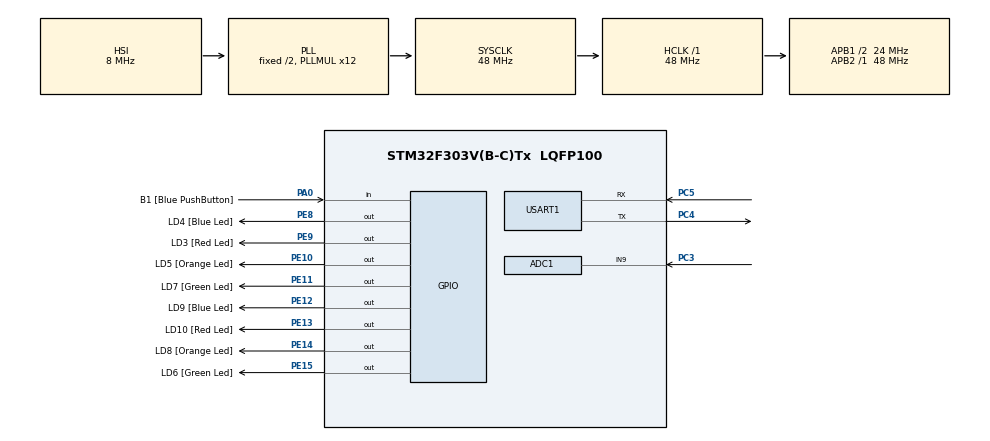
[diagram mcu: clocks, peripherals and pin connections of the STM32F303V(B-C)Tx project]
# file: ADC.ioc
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ADC1.Channel-0\#ChannelRegularConversion=ADC_CHANNEL_9
ADC1.Channel-1\#ChannelRegularConversion=ADC_CHANNEL_9
ADC1.Channel-2\#ChannelRegularConversion=ADC_CHANNEL_9
ADC1.ClockPrescaler=ADC_CLOCK_SYNC_PCLK_DIV2
ADC1.NbrOfConversion=3
ADC1.NbrOfConversionFlag=1
ADC1.Offset-0\#ChannelRegularConversion=0
ADC1.Offset-1\#ChannelRegularConversion=0
ADC1.Offset-2\#ChannelRegularConversion=0
ADC1.OffsetNumber-0\#ChannelRegularConversion=ADC_OFFSET_NONE
ADC1.OffsetNumber-1\#ChannelRegularConversion=ADC_OFFSET_NONE
ADC1.OffsetNumber-2\#ChannelRegularConversion=ADC_OFFSET_NONE
ADC1.Rank-0\#ChannelRegularConversion=1
ADC1.Rank-1\#ChannelRegularConversion=2
ADC1.Rank-2\#ChannelRegularConversion=3
ADC1.Resolution=ADC_RESOLUTION_8B
ADC1.SamplingTime-0\#ChannelRegularConversion=ADC_SAMPLETIME_1CYCLE_5
ADC1.SamplingTime-1\#ChannelRegularConversion=ADC_SAMPLETIME_1CYCLE_5
ADC1.SamplingTime-2\#ChannelRegularConversion=ADC_SAMPLETIME_1CYCLE_5
ADC1.SamplingTimeOPAMP-0\#ChannelRegularConversion=ADC_SAMPLETIME_19CYCLES_5
ADC1.SamplingTimeOPAMP-1\#ChannelRegularConversion=ADC_SAMPLETIME_19CYCLES_5
ADC1.SamplingTimeOPAMP-2\#ChannelRegularConversion=ADC_SAMPLETIME_19CYCLES_5
ADC1.master=1
Mcu.Family=STM32F3
Mcu.Name=STM32F303V(B-C)Tx
Mcu.Package=LQFP100
NVIC.PriorityGroup=NVIC_PRIORITYGROUP_0
PA0.GPIO_Label=B1 [Blue PushButton]
PA0.GPIO_Mode=GPIO_MODE_INPUT
PA0.GPIO_PuPd=GPIO_NOPULL
PA0.Signal=GPIO_Input
PA11.GPIO_Label=DM
PA11.Signal=USB_DM
PA12.GPIO_Label=DP
PA12.Signal=USB_DP
PA13.GPIO_Label=SWDIO
PA13.Signal=SYS_JTMS-SWDIO
PA14.GPIO_Label=SWCLK
PA14.Signal=SYS_JTCK-SWCLK
PB3.GPIO_Label=SWO
PB3.Signal=SYS_JTDO-TRACESWO
PC14-OSC32_IN.GPIO_Label=OSC32_IN
PC14-OSC32_IN.Signal=RCC_OSC32_IN
PC15-OSC32_OUT.GPIO_Label=OSC32_OUT
PC15-OSC32_OUT.Signal=RCC_OSC32_OUT
PC3.Signal=ADCx_IN9
PC4.Mode=Asynchronous
PC4.Signal=USART1_TX
PC5.Mode=Asynchronous
PC5.Signal=USART1_RX
PE10.GPIO_Label=LD5 [Orange Led]
PE10.GPIO_ModeDefaultOutputPP=GPIO_MODE_OUTPUT_PP
PE10.GPIO_PuPd=GPIO_NOPULL
PE10.GPIO_Speed=GPIO_SPEED_FREQ_LOW
PE10.Signal=GPIO_Output
PE11.GPIO_Label=LD7 [Green Led]
PE11.GPIO_ModeDefaultOutputPP=GPIO_MODE_OUTPUT_PP
PE11.GPIO_PuPd=GPIO_NOPULL
PE11.GPIO_Speed=GPIO_SPEED_FREQ_LOW
PE11.Signal=GPIO_Output
PE12.GPIO_Label=LD9 [Blue Led]
PE12.GPIO_ModeDefaultOutputPP=GPIO_MODE_OUTPUT_PP
PE12.GPIO_PuPd=GPIO_NOPULL
PE12.GPIO_Speed=GPIO_SPEED_FREQ_LOW
PE12.Signal=GPIO_Output
PE13.GPIO_Label=LD10 [Red Led]
PE13.GPIO_ModeDefaultOutputPP=GPIO_MODE_OUTPUT_PP
PE13.GPIO_PuPd=GPIO_NOPULL
PE13.GPIO_Speed=GPIO_SPEED_FREQ_LOW
PE13.Signal=GPIO_Output
PE14.GPIO_Label=LD8 [Orange Led]
PE14.GPIO_ModeDefaultOutputPP=GPIO_MODE_OUTPUT_PP
PE14.GPIO_PuPd=GPIO_NOPULL
PE14.GPIO_Speed=GPIO_SPEED_FREQ_LOW
PE14.Signal=GPIO_Output
PE15.GPIO_Label=LD6 [Green Led]
PE15.GPIO_ModeDefaultOutputPP=GPIO_MODE_OUTPUT_PP
PE15.GPIO_PuPd=GPIO_NOPULL
PE15.GPIO_Speed=GPIO_SPEED_FREQ_LOW
PE15.Signal=GPIO_Output
PE8.GPIO_Label=LD4 [Blue Led]
PE8.GPIO_ModeDefaultOutputPP=GPIO_MODE_OUTPUT_PP
PE8.GPIO_PuPd=GPIO_NOPULL
PE8.GPIO_Speed=GPIO_SPEED_FREQ_LOW
PE8.Signal=GPIO_Output
PE9.GPIO_Label=LD3 [Red Led]
PE9.GPIO_ModeDefaultOutputPP=GPIO_MODE_OUTPUT_PP
PE9.GPIO_PuPd=GPIO_NOPULL
PE9.GPIO_Speed=GPIO_SPEED_FREQ_LOW
PE9.Signal=GPIO_Output
PF0-OSC_IN.GPIO_Label=OSC_IN
PF0-OSC_IN.Signal=RCC_OSC_IN
PF1-OSC_OUT.GPIO_Label=OSC_OUT
PF1-OSC_OUT.Signal=RCC_OSC_OUT
ProjectManager.HeapSize=0x200
ProjectManager.StackSize=0x400
ProjectManager.TargetToolchain=STM32CubeIDE
RCC.AHBFreq_Value=48000000
RCC.APB1CLKDivider=RCC_HCLK_DIV2
RCC.APB1Freq_Value=24000000
RCC.APB1TimFreq_Value=48000000
RCC.APB2Freq_Value=48000000
RCC.APB2TimFreq_Value=48000000
RCC.CortexFreq_Value=48000000
RCC.HCLKFreq_Value=48000000
RCC.HSE_VALUE=8000000
RCC.HSI_VALUE=8000000
RCC.LSE_VALUE=32768
RCC.PLLMUL=RCC_PLL_MUL12
RCC.SYSCLKFreq_VALUE=48000000
RCC.SYSCLKSourceVirtual=RCC_SYSCLKSOURCE_PLLCLK
RCC.USBFreq_Value=48000000
SH.ADCx_IN9.0=ADC1_IN9,IN9-Single-Ended
USART1.VirtualMode-Asynchronous=VM_ASYNC
board=STM32F3DISCOVERY

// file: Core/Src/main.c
/* USER CODE BEGIN Header */
/**
  ******************************************************************************
  * @file           : main.c
  * @brief          : Main program body
  ******************************************************************************
  * @attention
  *
  * Copyright (c) 2025 STMicroelectronics.
  * All rights reserved.
  *
  * This software is licensed under terms that can be found in the LICENSE file
  * in the root directory of this software component.
  * If no LICENSE file comes with this software, it is provided AS-IS.
  *
  ******************************************************************************
  */
/* USER CODE END Header */
#include "main.h"

/* USER CODE BEGIN Includes */
#include <program.h>

/* USER CODE END Includes */

ADC_HandleTypeDef hadc1;

UART_HandleTypeDef huart1;

void SystemClock_Config(void);
static void MX_GPIO_Init(void);
static void MX_ADC1_Init(void);
static void MX_USART1_UART_Init(void);

int main(void)
{

  /* MCU Configuration--------------------------------------------------------*/

  /* Reset of all peripherals, Initializes the Flash interface and the Systick. */
  HAL_Init();

  /* Configure the system clock */
  SystemClock_Config();

  /* Initialize all configured peripherals */
  MX_GPIO_Init();
  MX_ADC1_Init();
  MX_USART1_UART_Init();
  /* USER CODE BEGIN 2 */
  extern __attribute__((noreturn)) void program(void);
  program();

  __builtin_unreachable();
  /* USER CODE END 2 */

  /* Infinite loop */
  while (1)
  {

  }
}

void SystemClock_Config(void)
{
  RCC_OscInitTypeDef RCC_OscInitStruct = {0};
  RCC_ClkInitTypeDef RCC_ClkInitStruct = {0};
  RCC_PeriphCLKInitTypeDef PeriphClkInit = {0};

  /** Initializes the RCC Oscillators according to the specified parameters
  * in the RCC_OscInitTypeDef structure.
  */
  RCC_OscInitStruct.OscillatorType = RCC_OSCILLATORTYPE_HSI;
  RCC_OscInitStruct.HSIState = RCC_HSI_ON;
  RCC_OscInitStruct.HSICalibrationValue = RCC_HSICALIBRATION_DEFAULT;
  RCC_OscInitStruct.PLL.PLLState = RCC_PLL_ON;
  RCC_OscInitStruct.PLL.PLLSource = RCC_PLLSOURCE_HSI;
  RCC_OscInitStruct.PLL.PLLMUL = RCC_PLL_MUL12;
  if (HAL_RCC_OscConfig(&RCC_OscInitStruct) != HAL_OK)
  {
    Error_Handler();
  }

  /** Initializes the CPU, AHB and APB buses clocks
  */
  RCC_ClkInitStruct.ClockType = RCC_CLOCKTYPE_HCLK|RCC_CLOCKTYPE_SYSCLK
                              |RCC_CLOCKTYPE_PCLK1|RCC_CLOCKTYPE_PCLK2;
  RCC_ClkInitStruct.SYSCLKSource = RCC_SYSCLKSOURCE_PLLCLK;
  RCC_ClkInitStruct.AHBCLKDivider = RCC_SYSCLK_DIV1;
  RCC_ClkInitStruct.APB1CLKDivider = RCC_HCLK_DIV2;
  RCC_ClkInitStruct.APB2CLKDivider = RCC_HCLK_DIV1;

  if (HAL_RCC_ClockConfig(&RCC_ClkInitStruct, FLASH_LATENCY_1) != HAL_OK)
  {
    Error_Handler();
  }
  PeriphClkInit.PeriphClockSelection = RCC_PERIPHCLK_USART1;
  PeriphClkInit.Usart1ClockSelection = RCC_USART1CLKSOURCE_PCLK2;
  if (HAL_RCCEx_PeriphCLKConfig(&PeriphClkInit) != HAL_OK)
  {
    Error_Handler();
  }
}

static void MX_ADC1_Init(void)
{

  ADC_MultiModeTypeDef multimode = {0};
  ADC_ChannelConfTypeDef sConfig = {0};

  /** Common config
  */
  hadc1.Instance = ADC1;
  hadc1.Init.ClockPrescaler = ADC_CLOCK_SYNC_PCLK_DIV2;
  hadc1.Init.Resolution = ADC_RESOLUTION_8B;
  hadc1.Init.ScanConvMode = ADC_SCAN_ENABLE;
  hadc1.Init.ContinuousConvMode = DISABLE;
  hadc1.Init.DiscontinuousConvMode = DISABLE;
  hadc1.Init.ExternalTrigConvEdge = ADC_EXTERNALTRIGCONVEDGE_NONE;
  hadc1.Init.ExternalTrigConv = ADC_SOFTWARE_START;
  hadc1.Init.DataAlign = ADC_DATAALIGN_RIGHT;
  hadc1.Init.NbrOfConversion = 3;
  hadc1.Init.DMAContinuousRequests = DISABLE;
  hadc1.Init.EOCSelection = ADC_EOC_SINGLE_CONV;
  hadc1.Init.LowPowerAutoWait = DISABLE;
  hadc1.Init.Overrun = ADC_OVR_DATA_OVERWRITTEN;
  if (HAL_ADC_Init(&hadc1) != HAL_OK)
  {
    Error_Handler();
  }

  /** Configure the ADC multi-mode
  */
  multimode.Mode = ADC_MODE_INDEPENDENT;
  if (HAL_ADCEx_MultiModeConfigChannel(&hadc1, &multimode) != HAL_OK)
  {
    Error_Handler();
  }

  /** Configure Regular Channel
  */
  sConfig.Channel = ADC_CHANNEL_9;
  sConfig.Rank = ADC_REGULAR_RANK_1;
  sConfig.SingleDiff = ADC_SINGLE_ENDED;
  sConfig.SamplingTime = ADC_SAMPLETIME_1CYCLE_5;
  sConfig.OffsetNumber = ADC_OFFSET_NONE;
  sConfig.Offset = 0;
  if (HAL_ADC_ConfigChannel(&hadc1, &sConfig) != HAL_OK)
  {
    Error_Handler();
  }

  /** Configure Regular Channel
  */
  sConfig.Rank = ADC_REGULAR_RANK_2;
  if (HAL_ADC_ConfigChannel(&hadc1, &sConfig) != HAL_OK)
  {
    Error_Handler();
  }

  /** Configure Regular Channel
  */
  sConfig.Rank = ADC_REGULAR_RANK_3;
  if (HAL_ADC_ConfigChannel(&hadc1, &sConfig) != HAL_OK)
  {
    Error_Handler();
  }

}

static void MX_USART1_UART_Init(void)
{

  huart1.Instance = USART1;
  huart1.Init.BaudRate = 38400;
  huart1.Init.WordLength = UART_WORDLENGTH_8B;
  huart1.Init.StopBits = UART_STOPBITS_1;
  huart1.Init.Parity = UART_PARITY_NONE;
  huart1.Init.Mode = UART_MODE_TX_RX;
  huart1.Init.HwFlowCtl = UART_HWCONTROL_NONE;
  huart1.Init.OverSampling = UART_OVERSAMPLING_16;
  huart1.Init.OneBitSampling = UART_ONE_BIT_SAMPLE_DISABLE;
  huart1.AdvancedInit.AdvFeatureInit = UART_ADVFEATURE_NO_INIT;
  if (HAL_UART_Init(&huart1) != HAL_OK)
  {
    Error_Handler();
  }

}

static void MX_GPIO_Init(void)
{
  GPIO_InitTypeDef GPIO_InitStruct = {0};

  /* GPIO Ports Clock Enable */
  __HAL_RCC_GPIOC_CLK_ENABLE();
  __HAL_RCC_GPIOF_CLK_ENABLE();
  __HAL_RCC_GPIOA_CLK_ENABLE();
  __HAL_RCC_GPIOE_CLK_ENABLE();
  __HAL_RCC_GPIOB_CLK_ENABLE();

  /*Configure GPIO pin Output Level */
  HAL_GPIO_WritePin(GPIOE, LD4_Pin|LD3_Pin|LD5_Pin|LD7_Pin
                          |LD9_Pin|LD10_Pin|LD8_Pin|LD6_Pin, GPIO_PIN_RESET);

  /*Configure GPIO pin : B1_Pin */
  GPIO_InitStruct.Pin = B1_Pin;
  GPIO_InitStruct.Mode = GPIO_MODE_INPUT;
  GPIO_InitStruct.Pull = GPIO_NOPULL;
  HAL_GPIO_Init(B1_GPIO_Port, &GPIO_InitStruct);

  /*Configure GPIO pins : LD4_Pin LD3_Pin LD5_Pin LD7_Pin
                           LD9_Pin LD10_Pin LD8_Pin LD6_Pin */
  GPIO_InitStruct.Pin = LD4_Pin|LD3_Pin|LD5_Pin|LD7_Pin
                          |LD9_Pin|LD10_Pin|LD8_Pin|LD6_Pin;
  GPIO_InitStruct.Mode = GPIO_MODE_OUTPUT_PP;
  GPIO_InitStruct.Pull = GPIO_NOPULL;
  GPIO_InitStruct.Speed = GPIO_SPEED_FREQ_LOW;
  HAL_GPIO_Init(GPIOE, &GPIO_InitStruct);

  /*Configure GPIO pins : DM_Pin DP_Pin */
  GPIO_InitStruct.Pin = DM_Pin|DP_Pin;
  GPIO_InitStruct.Mode = GPIO_MODE_AF_PP;
  GPIO_InitStruct.Pull = GPIO_NOPULL;
  GPIO_InitStruct.Speed = GPIO_SPEED_FREQ_HIGH;
  GPIO_InitStruct.Alternate = GPIO_AF14_USB;
  HAL_GPIO_Init(GPIOA, &GPIO_InitStruct);

}

void Error_Handler(void)
{
  __disable_irq();
  while (1)
  {
  }
}
